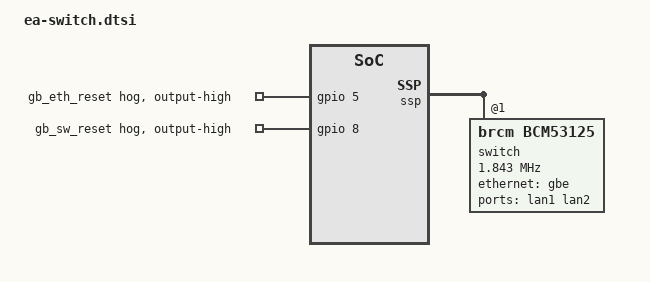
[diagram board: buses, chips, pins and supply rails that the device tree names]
// SPDX-License-Identifier: GPL-2.0
/*
 * BCM53125 managed switch on SSP chip-select 1 (the `switch` feature). SPI mode 3
 * is required: mode 0 never answers. Port 5 is the CPU port; leave it without
 * fixed-link. See site/src/content/docs/ea/switch.md.
 */
#define EA_LINE_5	"gb_eth_reset"
#define EA_LINE_8	"gb_sw_reset"

&gpio {
	gb-eth-reset-hog {
		gpio-hog;
		gpios = <5 GPIO_ACTIVE_HIGH>;
		output-high;
		line-name = "gb_eth_reset";
	};
	gb-sw-reset-hog {
		gpio-hog;
		gpios = <8 GPIO_ACTIVE_HIGH>;
		output-high;
		line-name = "gb_sw_reset";
	};
};

&ssp {
	switch@1 {
		compatible = "brcm,bcm53125";
		reg = <1>;
		spi-max-frequency = <1843200>;
		spi-cpol;
		spi-cpha;

		switch_ports: ports {
			#address-cells = <1>;
			#size-cells = <0>;

			port@1 {
				reg = <1>;
				label = "lan1";
			};

			port@2 {
				reg = <2>;
				label = "lan2";
			};

			port@5 {
				reg = <5>;
				ethernet = <&gbe>;
			};
		};
	};
};
